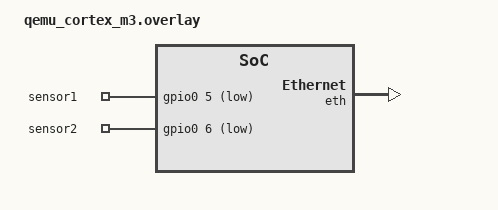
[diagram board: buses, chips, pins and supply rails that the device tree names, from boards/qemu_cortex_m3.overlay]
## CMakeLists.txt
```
# SPDX-License-Identifier: Apache-2.0

cmake_minimum_required(VERSION 3.20.0)

set(ZEPHYR_EXTRA_MODULES "${CMAKE_CURRENT_SOURCE_DIR}/camera_service")

find_package(Zephyr REQUIRED HINTS $ENV{ZEPHYR_BASE})
project(tracker)

include_directories(./include/)

file(GLOB_RECURSE SRC ${CMAKE_SOURCE_DIR} "src/*.c")

target_sources(app PRIVATE ${SRC})
```

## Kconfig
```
menu "Zephyr"
source "Kconfig.zephyr"
endmenu

menu "Tracker Configuration"
    menu "Vehicle Speed Detection"

    config VEHICLE_SPEED_DETECTION
        bool "Enable Vehicle Speed Detection"
        default y
        help
            This option enables the vehicle speed detection feature in the system.
            It allows the system to monitor and report the speed of the vehicle in real-time.
            This feature is essential for applications that require speed monitoring and control.
    config RADAR_SENSOR_DISTANCE_MM
        int "Distance between sensors (mm)"
        range 100 1000
        depends on VEHICLE_SPEED_DETECTION
        help
            The physical distance between the two magnetic sensors in millimeters.
            This value is used to calculate vehicle speed when a vehicle passes
            over both sensors. A larger distance generally provides more accurate
            speed measurements but requires more space for installation.
    
    config RADAR_SPEED_LIMIT_KMH
        int "Maximum speed permited (km/h)"
        range 10 300
        default 60
        depends on VEHICLE_SPEED_DETECTION
        help
            The maximum allowed vehicle speed in kilometers per hour.
            This value is used to trigger alarms or log over-speed events
            when a vehicle's calculated speed exceeds this limit.
            Adjust this setting according to local traffic regulations.

    config SENSOR_DEBOUNCE_MS
        int "Sensor debounce time (ms)"
        range 10 500
        default 50
        depends on VEHICLE_SPEED_DETECTION
        help
            The debounce time for the sensors in milliseconds. This is the time
            that the system will wait after detecting a signal from one sensor
            before considering it valid. A longer debounce time can help to filter
            out noise and false signals, but may also delay the detection of a vehicle.
            A value of 10ms is generally a good starting point.
    endmenu
    
    menu "Thread Configuration"
        config THREAD_STACK_SIZE
            int "Max stack size used in threads"
            default 1024
            help
                The maximum stack size used in threads. This value is used to
                allocate the stack space for each thread. A larger stack size
                allows for more complex operations and more local variables,
                but also consumes more memory. A value of 1024 bytes is generally
                a good starting point for most applications.

        config THREAD_PRIORITY
            int "Thread priority"
            default 5
            range 0 10
            help
                The priority of the threads in the system. This value determines
                the order in which threads are scheduled for execution. A higher
                priority value means that the thread will be executed before
                lower priority threads. A value of 5 is generally a good starting
                point for most applications.
    endmenu

    menu "SNTP Configuration"
        config DEFAULT_SNTP_SERVER
            string "Default SNTP server"
            default "200.160.7.186"
            help
                The default SNTP server to use for time synchronization. This
                server will be used if no other server is specified. The server
                should be reachable from the network and should support SNTP
                requests.

        config TIME_SYNC_INTERVAL_MS
            int "Time synchronization interval (ms)"
            default 3600000
            range 60000 86400000
            help
                The interval in milliseconds at which the system will synchronize
                its time with the SNTP server. A value of 3600000 ms (1 hour) is
                a good starting point for most applications, but can be adjusted
                based on the application's requirements.
        
        config NUMBER_OF_RETRIES
            int "Number of retries for SNTP requests"
            default 3
            range 1 10
            help
                The number of times the system will retry to synchronize time with
                the SNTP server if the initial request fails. A value of 3 is a good
                starting point, but can be adjusted based on network reliability and
                application requirements. 
    endmenu

    menu "HTTP Client Configuration"
        config SERVER_HOSTNAME
            string "Server hostname"
            default "192.168.0.12"
            help
                The hostname of the server to which the HTTP client will connect.
                This should be a valid hostname that resolves to an IP address
                reachable from the device. The default is set to "example.com",
                but should be changed to the actual server you want to connect to.

        config SERVER_PORT
            int "Server port"
            default 5000
            range 1 65535
            help
                The port number on which the server is listening for HTTP requests.
                The default is set to 80, which is the standard port for HTTP traffic.
                If your server uses a different port, you should change this value accordingly.

        config SERVER_URL
            string "Server URL"
            default "/api/speed-infractions"
            help
                The URL path on the server to which the HTTP client will send requests.
                This should be set to the specific endpoint that the server expects for
                receiving data. The default is set to "/api/speed-infractions", but should be changed
                to match your server's API.
        
        config CLIENT_MAX_RECV_BUF_LEN
            int "Maximum receive buffer length"
            default 1024
            range 256 8192
            help
                The maximum length of the receive buffer for the HTTP client.
                This value determines how much data the client can read from the server
                in a single response. A larger buffer allows for larger responses,
                but consumes more memory. A value of 1024 bytes is generally a good starting point.
        
        config RECV_BUF_LEN
            int "Receive buffer length"
            default 512
            range 128 4096
            help
                The length of the receive buffer used by the HTTP client. This buffer
                is used to store incoming data from the server. A larger buffer allows
                for more data to be received at once, but also consumes more memory.
                A value of 512 bytes is generally a good starting point for most applications.
        
        config RECV_TIMEOUT_MS
            int "Receive timeout (ms)"
            default 5000
            range 1000 30000
            help
                The timeout in milliseconds for receiving data from the server.
                If no data is received within this time, the client will consider
                the request failed. A value of 5000 ms (5 seconds) is a good starting point,
                but can be adjusted based on network conditions and application requirements.

    endmenu

    menu "Simulation Configuration"
        config SYSTEM_SIMULATION
            bool "Enable system simulation"
            default n
            help
                This option enables the system simulation mode. In this mode,
                the system will simulate the behavior of the vehicle speed detection
                system without actually using any hardware. This is useful for
                testing and debugging purposes.
        config SIMULATION_SPEED
            int "Simulation speed (km/h)"
            range 0 300
            default 60
            depends on SYSTEM_SIMULATION
            help
                The speed of the simulated vehicle in kilometers per hour. This
                value is used to simulate the behavior of the vehicle speed detection
                system. A value of 60 km/h is generally a good starting point for
                most applications.
    endmenu
endmenu
```

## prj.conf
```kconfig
# ===== GENERAL SYSTEM CONFIGURATION =====
CONFIG_BOOT_BANNER=n
CONFIG_POSIX_API=y
CONFIG_MAIN_STACK_SIZE=4096
CONFIG_SYSTEM_SIMULATION=y

# ===== HARDWARE PERIPHERALS =====
# GPIO Configuration
CONFIG_GPIO=y
CONFIG_GPIO_STELLARIS=y
CONFIG_GPIO_GET_CONFIG=y

# RTC Configuration
CONFIG_RTC=y

# Random Number Generation
CONFIG_ENTROPY_GENERATOR=y
CONFIG_TEST_RANDOM_GENERATOR=y

# ===== STORAGE AND SETTINGS =====
CONFIG_SETTINGS=y
CONFIG_FLASH=y
CONFIG_FLASH_MAP=y
CONFIG_NVS=y

# ===== NETWORKING BASE =====
CONFIG_NETWORKING=y
CONFIG_NET_CONNECTION_MANAGER=y
CONFIG_NET_SOCKETS=y
CONFIG_NET_IPV4=y
CONFIG_NET_IPV6=y
CONFIG_NET_QEMU_ETHERNET=y
CONFIG_NET_QEMU_USER=y

# ===== NETWORK PROTOCOLS =====
CONFIG_NET_UDP=y
CONFIG_NET_TCP=y
CONFIG_SNTP=y
CONFIG_NET_SOCKETS_POLL_MAX=5

# ===== NETWORK INTERFACE CONFIGURATION =====
CONFIG_NET_CONFIG_SETTINGS=y
CONFIG_NET_CONFIG_AUTO_INIT=y
CONFIG_NET_CONFIG_NEED_IPV4=y
CONFIG_NET_DHCPV4=y
CONFIG_NET_DHCPV6=y
# CONFIG_NET_CONFIG_MY_IPV4_ADDR="192.168.0.100"
# CONFIG_NET_CONFIG_MY_IPV4_NETMASK="255.255.255.0"
# CONFIG_NET_CONFIG_MY_IPV4_GW="192.168.0.1"

# ===== ETHERNET CONFIGURATION =====
CONFIG_NET_L2_ETHERNET=y
CONFIG_ETH_STELLARIS=y
CONFIG_NET_SLIP_TAP=n

# ===== DNS CONFIGURATION =====
CONFIG_DNS_RESOLVER=y
CONFIG_DNS_SERVER_IP_ADDRESSES=y
CONFIG_DNS_SERVER1="8.8.8.8"

# ===== NETWORK BUFFERS =====
CONFIG_NET_BUF_RX_COUNT=16
CONFIG_NET_BUF_TX_COUNT=16
CONFIG_NET_PKT_RX_COUNT=16
CONFIG_NET_PKT_TX_COUNT=16
CONFIG_NET_CONTEXT_NET_PKT_POOL=y

# ===== NETWORK MANAGEMENT =====
CONFIG_NET_MGMT=y
CONFIG_NET_MGMT_EVENT=y
CONFIG_NET_MGMT_EVENT_INFO=y

# ===== LOGGING =====
CONFIG_LOG=y
CONFIG_LOG_DEFAULT_LEVEL=3
CONFIG_NET_LOG=n

# ===== CAMERA SERVICE =====
CONFIG_ZBUS=y
CONFIG_ZBUS_MSG_SUBSCRIBER=y
CONFIG_TEST_RANDOM_GENERATOR=y
CONFIG_QEMU_ICOUNT=n

# ===== DISPLAY DRIVER =====
CONFIG_DISPLAY=y
CONFIG_DUMMY_DISPLAY=y

# ===== HTTP CLIENT =====
CONFIG_HTTP_CLIENT=y

# ===== JSON LIBRARY =====
CONFIG_JSON_LIBRARY=y
```

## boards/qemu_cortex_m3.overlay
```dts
#include <zephyr/dt-bindings/gpio/gpio.h>
/ {
    aliases {
        sensor1 = &gpio0;
        sensor2 = &gpio0;
    };

    sensors {
        compatible = "gpio-keys";
        debounce-interval-ms = <10>;
        sensor1: sensor_1{
            gpios = <&gpio0 5 GPIO_ACTIVE_LOW>;
        };

        sensor2: sensor_2{
            gpios = <&gpio0 6 GPIO_ACTIVE_LOW>;
        };
    };
    
    dummy_dc: dummy_display_controller {
        compatible = "zephyr,dummy-dc";
        width = <320>;
        height = <240>;
        status = "okay";
    };
    chosen {
        zephyr,display = &dummy_dc;
    };
};
&eth {
    status = "okay";
};
```

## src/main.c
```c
#include "camera_handler.h"
#include "camera_service.h"
#include "data_http_client.h"
#include "display.h"
#include "rtc.h"
#include "sensors.h"
#include "validate_plate.h"

LOG_MODULE_REGISTER(main, LOG_LEVEL_INF);

ZBUS_MSG_SUBSCRIBER_DEFINE(sensor_consumer);

static struct rtc_time latest_time;
static bool time_valid = false;

/**
 * @brief Validate the speed data and process it if valid.
 *
 * @param speed Speed in km/h to validate.
 * @param time_valid Indicates if the time data is valid.
 * @param latest_time Pointer to the latest time structure.
 * @return int
 */
static int validate_and_process_speed(int32_t speed, bool time_valid, struct rtc_time *latest_time);

int main(void)
{
	int err;
	struct sensor_event evt;
	const struct zbus_channel *evt_chan;

	err = display_speed_init();
	if (err < 0) {
		LOG_ERR("Failed to initialize display: %d", err);
		return 0;
	}

	err = sensors_init();
	if (err < 0) {
		LOG_ERR("Failed to initialize sensors");
		return 0;
	}

	LOG_INF("Vehicle detection system started");

	while (1) {
		if (k_msgq_get(&time_msgq, &latest_time, K_NO_WAIT) == 0) {
			time_valid = true;
			LOG_DBG("Time updated: %02d:%02d:%02d %02d/%02d/%04d", latest_time.tm_hour,
				latest_time.tm_min, latest_time.tm_sec, latest_time.tm_mday,
				latest_time.tm_mon + 1, latest_time.tm_year);
		}

		k_sleep(K_MSEC(500));

#ifdef CONFIG_SYSTEM_SIMULATION
		err = sensors_simulate_vehicle_detection(90);
		if (err < 0) {
			LOG_ERR("Failed to simulate vehicle detection: %d", err);
		}
#endif

		err = zbus_sub_wait_msg(&sensor_consumer, &evt_chan, &evt, K_FOREVER);
		if (err < 0) {
			if (err == -EAGAIN) {
				continue;
			}

			LOG_ERR("Failed to wait for sensor event: %d", err);
			continue;
		}

		if (evt.vehicle_detected) {
			int32_t speed = evt.speed_kmh;

			err = validate_and_process_speed(speed, time_valid, &latest_time);
			if (err < 0) {
				LOG_ERR("Failed to process speed data: %d", err);
				continue;
			}
		}
	}
}

static int validate_and_process_speed(int32_t speed, bool time_valid, struct rtc_time *latest_time)
{
	char timestamp[32];

	if (speed < 0 || speed > 500) {
		LOG_WRN("Invalid speed value: %d km/h - ignoring", speed);
		return -EINVAL;
	}

	char speed_text[32];
	snprintf(speed_text, sizeof(speed_text), "Speed: %d km/h", speed);

	int err = display_speed_show(speed_text);
	if (err < 0) {
		LOG_ERR("Failed to write speed to display: %d", err);
		return err;
	}

	if (speed > CONFIG_RADAR_SPEED_LIMIT_KMH) {
		LOG_INF("Speed violation detected! %d km/h", speed);

		if (time_valid && latest_time != NULL) {
			LOG_INF("Speed violation at %02d:%02d:%02d %02d/%02d/%04d",
				latest_time->tm_hour, latest_time->tm_min, latest_time->tm_sec,
				latest_time->tm_mday, latest_time->tm_mon + 1,
				latest_time->tm_year);
			const char *plate = NULL;
			const char *hash = NULL;
			char country[3];

			if (camera_handler_capture(&plate, &hash) == 0) {
				LOG_INF("Captured plate: %s", plate);
				LOG_DBG("Captured image hash: %s", hash);
				if (is_valid_mercosul_plate(plate, country)) {
					LOG_INF("Captured plate is valid and is from: %s", country);
					if (time_valid) {
						snprintf(timestamp, sizeof(timestamp),
							 "%02d:%02d:%02d %02d/%02d/%04d",
							 latest_time->tm_hour, latest_time->tm_min,
							 latest_time->tm_sec, latest_time->tm_mday,
							 latest_time->tm_mon + 1,
							 latest_time->tm_year);
					} else {
						strncpy(timestamp, "N/A", sizeof(timestamp));
					}
					err = send_infraction_data(speed, plate, country,
								   timestamp);
					if (err < 0) {
						LOG_ERR("Failed to send infraction data: %d", err);
					} else {
						LOG_INF("Infraction data sent successfully");
					}
				} else {
					LOG_INF("Captured plate is invalid!");
					/*TODO: send to python server that the plate is not valid*/
					err = send_infraction_data(speed, plate, "N/A", "N/A");
					if (err < 0) {
						LOG_ERR("Failed to send infraction data for "
							"invalid plate: %d",
							err);
					} else {
						LOG_INF("Infraction data for invalid plate sent "
							"successfully");
					}
				}
			} else {
				LOG_ERR("Failed to capture plate");
				return -EIO;
			}
		} else {
			struct rtc_time now;

			int ret = tracker_get_time(&now);
			if (ret == 0) {
				LOG_INF("Speed detected at %02d:%02d:%02d", now.tm_hour, now.tm_min,
					now.tm_sec);
			} else {
				LOG_ERR("Failed to get SNTP time");
			}
		}
	}

	return 0;
}
```

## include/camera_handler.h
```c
#include <zephyr/kernel.h>
#include <zephyr/logging/log.h>

/**
 * @brief Captures a simulated image via camera.
 *
 * Triggers the camera service via ZBUS, waits for a response, and returns the data.
 *
 * @param[out] plate Pointer to the captured license plate string.
 * @param[out] hash Pointer to the image hash string.
 * @return 0 on success, negative value on error.
 */
int camera_handler_capture(const char **plate, const char **hash);
```

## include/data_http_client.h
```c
#ifndef DATA_HTTP_CLIENT_H
#define DATA_HTTP_CLIENT_H

#include <zephyr/kernel.h>
#include <zephyr/logging/log.h>
#include <zephyr/net/http/client.h>
#include <zephyr/net/socket.h>

#include <stdint.h>

/**
 * @brief Send infraction data to the server.
 *
 * @param speed Speed in km/h of the vehicle.
 * @param plate Vehicle license plate number.
 * @param country Country code of the vehicle.
 * @param timestamp Timestamp of the infraction in ISO 8601 format (YYYY-MM-DDTHH:MM:SSZ).
 * @return 0 on success, negative error code on failure.
 */
int send_infraction_data(int32_t speed, const char *plate, const char *country,
			 const char *timestamp);

#endif // DATA_HTTP_CLIENT_H
```

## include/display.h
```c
#ifndef DISPLAY_H
#define DISPLAY_H
#include <zephyr/device.h>
#include <zephyr/drivers/display.h>
#include <zephyr/logging/log.h>

/**
 * @brief Initialize the display device and turn off display blanking.
 *
 * @return 0 on success, otherwise negative error code on failure.
 */
int display_speed_init(void);

/**
 * @brief Show the speed on the display.
 *
 * @param text The text to display, typically the speed in km/h.
 * @return 0 on success, otherwise negative error code on failure.
 */
int display_speed_show(const char *text);

#endif /* DISPLAY_H */
```

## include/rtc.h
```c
#ifndef RTC_H
#define RTC_H

#include <zephyr/device.h>
#include <zephyr/drivers/rtc.h>
#include <zephyr/kernel.h>
#include <zephyr/logging/log.h>
#include <zephyr/net/net_ip.h>
#include <zephyr/net/sntp.h>
#include <zephyr/net/socket.h>
#include <zephyr/settings/settings.h>

#include <time.h>

#include <stdbool.h>
#include <stdint.h>

extern struct k_msgq time_msgq;

/**
 * @brief Function to get the current time from SNTP server.
 *
 * @param time Pointer to the rtc_time structure to store the retrieved time.
 * @return int 0 on success, negative error code on failure.
 */
int tracker_get_time(struct rtc_time *time);

#endif /* RTC_H */
```

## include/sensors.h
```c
#ifndef SENSORS_H
#define SENSORS_H

#include "zephyr/zbus/zbus.h"
#include <zephyr/device.h>
#include <zephyr/drivers/gpio.h>
#include <zephyr/kernel.h>
#include <zephyr/logging/log.h>

#include <stdbool.h>
#include <stdint.h>

struct sensor_event {
	int32_t speed_kmh;
	bool vehicle_detected;
};

/**
 * @brief Construct a new zbus chan declare object
 *
 */
ZBUS_CHAN_DECLARE(chan_sensors_evt);

/**
 * @brief Initialize the sensors and configure GPIO pins.
 *
 * @return 0 on success, otherwise negative error code on failure.
 */
int sensors_init(void);

/**
 * @brief Trigger a sensor manually for testing purposes.
 *
 * @param sensor_num Sensor number to trigger (1 or 2).
 * @return 0 on success, otherwise negative error code on failure.
 */
int sensors_simulate_vehicle_detection(int32_t speed_kmh);

#endif /* SENSORS_H */
```

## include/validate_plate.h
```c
#ifndef VALIDATE_PLATE_H
#define VALIDATE_PLATE_H

#include <ctype.h>
#include <string.h>
#include <zephyr/kernel.h>

/**
 * @brief Validates a license plate and determines its country of origin.
 *
 * This function checks if the given license plate string matches the format
 * of a valid plate from Brazil (BR), Argentina (AR), or Paraguay (PY).
 * If valid, it copies the corresponding country code into the output parameter.
 *
 * @param plate        The license plate string to validate.
 * @param country_out  A pointer to a char array where the country code ("BR", "AR", "PY") will be
 * stored if valid.
 *
 * @return true if the plate is valid and matches one of the known formats, false otherwise.
 */

bool is_valid_mercosul_plate(const char *plate, char *country_out);

#endif /* VALIDATE_PLATE_H */
```

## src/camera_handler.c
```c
#include "camera_handler.h"
#include "camera_service.h"

LOG_MODULE_REGISTER(camera_handler, LOG_LEVEL_INF);

int camera_handler_capture(const char **plate, const char **hash)
{
	int ret = camera_api_capture(K_MSEC(500));
	if (ret < 0) {
		LOG_ERR("Failed to trigger camera capture");
		return ret;
	}

	struct msg_camera_evt msg;

	if (zbus_chan_read(&chan_camera_evt, &msg, K_MSEC(500)) != 0) {
		LOG_ERR("Timeout waiting for camera data");
		return -1;
	}

	if (msg.type == MSG_CAMERA_EVT_TYPE_DATA && msg.captured_data) {
		*plate = msg.captured_data->plate;
		*hash = msg.captured_data->hash;
		return 0;
	} else if (msg.type == MSG_CAMERA_EVT_TYPE_ERROR) {
		LOG_ERR("Camera error: %d", msg.error_code);
		return msg.error_code;
	}

	LOG_ERR("Invalid camera message type");
	return -1;
}
```

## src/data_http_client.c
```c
#include <errno.h>
#include <zephyr/kernel.h>
#include <zephyr/logging/log.h>
#include <zephyr/net/http/client.h>
#include <zephyr/net/socket.h>

#include "data_http_client.h"

LOG_MODULE_REGISTER(data_http_client, LOG_LEVEL_INF);

static char recv_buf_data[CONFIG_RECV_BUF_LEN];
static char response_buf[CONFIG_CLIENT_MAX_RECV_BUF_LEN];

/**
 * @brief Callback function to handle HTTP responses
 *
 * @param rsp Pointer to the HTTP response structure
 * @param final_data Final call status of the HTTP response
 * @param user_data User data pointer (not used in this case)
 */
static void response_cb(struct http_response *rsp, enum http_final_call final_data,
			void *user_data);

/**
 * @brief Prepare JSON data for sending infraction data
 *
 * @param buffer pointer to the buffer where JSON data will be stored
 * @param len size of the buffer
 * @param speed Speed in km/h
 * @param plate Plate number of the vehicle
 * @param country Respective country of the vehicle's plate
 * @param timestamp Timestamp of the infraction in "HH:MM:SS DD/MM/YYYY" format, or NULL if not
 * available
 * @return 0 if successful, otherwise negative error code
 */
static int prepare_json_data(char *buffer, size_t len, int32_t speed, const char *plate,
			     const char *country, const char *timestamp);

/**
 * @brief Fuction to connect to the HTTP server
 *
 * @return 0 if successful, otherwise negative error code
 */
static int connect_http_client(void);

static void response_cb(struct http_response *rsp, enum http_final_call final_data, void *user_data)
{
	if (final_data == HTTP_DATA_FINAL) {
		LOG_INF("Response status %s (%d)", rsp->http_status, rsp->http_status_code);
	}

	if (rsp->body_frag_len > 0) {
		LOG_INF("Response body: %.*s", rsp->body_frag_len, (char *)rsp->body_frag_start);
	}
}

static int prepare_json_data(char *buffer, size_t len, int32_t speed, const char *plate,
			     const char *country, const char *timestamp)
{
	int offset = 0;

	offset = snprintf(buffer, len, "{\"speed\":%d,\"plate\":\"%s\",\"country\":\"%s\"", speed,
			  plate, country);

	if (timestamp != NULL) {
		offset +=
			snprintf(buffer + offset, len - offset, ",\"timestamp\":\"%s\"", timestamp);
	}

	offset += snprintf(buffer + offset, len - offset, "}");

	LOG_INF("offset: %d, buffer: %s", offset, buffer);

	return offset;
}

static int connect_http_client(void)
{
	int sock;
	int ret;
	struct sockaddr_in addr;

	sock = socket(AF_INET, SOCK_STREAM, IPPROTO_TCP);
	if (sock < 0) {
		LOG_ERR("Failed to create socket: %d", errno);
		return -errno;
	}

	memset(&addr, 0, sizeof(addr));
	addr.sin_family = AF_INET;
	addr.sin_port = htons(CONFIG_SERVER_PORT);

	ret = inet_pton(AF_INET, CONFIG_SERVER_HOSTNAME, &addr.sin_addr);
	if (ret <= 0) {
		LOG_ERR("Invalid server address: %s", CONFIG_SERVER_HOSTNAME);
		close(sock);
		return -EINVAL;
	}

	ret = connect(sock, (struct sockaddr *)&addr, sizeof(addr));
	if (ret < 0) {
		LOG_ERR("Cannot connect to %s:%d (%d)", CONFIG_SERVER_HOSTNAME, CONFIG_SERVER_PORT,
			-errno);
		close(sock);
		return -errno;
	}

	return sock;
}

int send_infraction_data(int32_t speed, const char *plate, const char *country,
			 const char *timestamp)
{
	struct http_request req;
	int sock;
	int ret;
	char json_data[512];
	size_t json_len;

	json_len =
		prepare_json_data(json_data, sizeof(json_data), speed, plate, country, timestamp);

	LOG_INF("Sending infraction data: %s", json_data);

	sock = connect_http_client();
	if (sock < 0) {
		return sock;
	}

	static const char *headers[] = {"Content-Type: application/json\r\n",
					"Connection: close\r\n", "Accept: application/json\r\n",
					NULL};

	memset(&req, 0, sizeof(req));
	req.method = HTTP_POST;
	req.url = CONFIG_SERVER_URL;
	req.host = CONFIG_SERVER_HOSTNAME;
	req.protocol = "HTTP/1.1";
	req.payload = json_data;
	req.payload_len = json_len;
	req.header_fields = headers;
	req.response = response_cb;
	req.recv_buf = recv_buf_data;
	req.recv_buf_len = sizeof(recv_buf_data);

	ret = http_client_req(sock, &req, CONFIG_RECV_TIMEOUT_MS, response_buf);

	close(sock);

	if (ret < 0) {
		LOG_ERR("HTTP request failed: %d", ret);
		return ret;
	}

	LOG_INF("HTTP request completed, response length: %d", ret);
	return 0;
}
```

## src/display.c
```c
#include "display.h"

LOG_MODULE_REGISTER(display, LOG_LEVEL_INF);

const struct device *display_dev;

/**
 * @brief Render the given text on the display.
 *
 * @param text The text to display.
 * @return 0 on success, otherwise negative error code on failure.
 */
static int display_speed_write(const char *text);

/**
 * @brief Clear the speed display by writing a blank buffer to the display.
 *
 * @return 0 on success, otherwise negative error code on failure.
 */
static int display_speed_clear(void);

int display_speed_init(void)
{
	display_dev = DEVICE_DT_GET(DT_CHOSEN(zephyr_display));
	if (!device_is_ready(display_dev)) {
		LOG_ERR("Display device not ready");
		return -ENODEV;
	}

	LOG_INF("Display device initialized: %s", display_dev->name);
	int ret = display_blanking_off(display_dev);
	if (ret < 0) {
		LOG_ERR("Failed to turn off display blanking: %d", ret);
		return ret;
	}
	LOG_INF("Display blanking turned off");
	return 0;
}

static int display_speed_clear(void)
{
	if (!display_dev) {
		LOG_ERR("Display device not initialized");
		return -ENODEV;
	}

	struct display_buffer_descriptor desc = {
		.buf_size = 1,
		.width = 320,
		.height = 240,
		.pitch = 320,
	};

	uint8_t clear_buf[1] = {0};
	return display_write(display_dev, 0, 0, &desc, clear_buf);
}

static int display_speed_write(const char *text)
{
	int err = 0;
	if (!display_dev) {
		LOG_ERR("Display device not initialized");
		return -ENODEV;
	}

	err = display_speed_clear();
	if (err < 0) {
		LOG_ERR("Failed to clear display: %d", err);
		return err;
	}

	struct display_buffer_descriptor desc = {
		.buf_size = strlen(text),
		.width = 320,
		.height = 240,
		.pitch = 320,
	};

	return display_write(display_dev, 0, 0, &desc, (const uint8_t *)text);
}

int display_speed_show(const char *text)
{
	if (!display_dev) {
		LOG_ERR("Display device not initialized");
		return -ENODEV;
	}

	int err = display_speed_write(text);
	if (err < 0) {
		LOG_ERR("Failed to write text to display: %d", err);
		return err;
	}

	LOG_INF("Speed: %s", text);
	return 0;
}
```

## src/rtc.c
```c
#include "rtc.h"

LOG_MODULE_REGISTER(rtc, LOG_LEVEL_DBG);

#define TIME_QUEUE_SIZE 5

K_MSGQ_DEFINE(time_msgq, sizeof(struct rtc_time), TIME_QUEUE_SIZE, 4);

static struct sys_time {
	char server[64];
	int8_t timezone;
} self = {.server = CONFIG_DEFAULT_SNTP_SERVER, .timezone = 0};

/**
 * @brief Function to get the current time from SNTP server.
 *
 * @param p1 Void pointer to the first parameter (not used).
 * @param p2 Void pointer to the second parameter (not used).
 * @param p3 Void pointer to the third parameter (not used).
 */
static void time_thread_function(void *p1, void *p2, void *p3);

int tracker_get_time(struct rtc_time *time)
{
	struct sntp_ctx ctx;
	struct sntp_time datetime;
	struct sockaddr_in server_addr;
	int err = 0;

	server_addr.sin_family = AF_INET;
	server_addr.sin_port = htons(123);

	memset(&ctx, 0, sizeof(ctx));

	err = inet_pton(AF_INET, self.server, &server_addr.sin_addr);

	if (err < 0) {
		LOG_ERR("Invalid SNTP server address: %d", err);
		return -EINVAL;
	}

	err = sntp_init(&ctx, (struct sockaddr *)&server_addr, sizeof(struct sockaddr_in));

	if (err < 0) {
		LOG_ERR("Failed to initialize SNTP: %d", err);
		return err;
	}

	err = sntp_query(&ctx, 4 * MSEC_PER_SEC, &datetime);

	if (err < 0) {
		LOG_ERR("Failed to query SNTP: %d", err);
		goto close_sntp;
	}

close_sntp:

	sntp_close(&ctx);

	time_t unix_time = datetime.seconds;
	unix_time += self.timezone * 3600;

	struct tm tm_info;
	if (gmtime_r(&unix_time, &tm_info) == NULL) {
		LOG_ERR("Failed to convert time to UTC");
		return -EINVAL;
	}

	time->tm_sec = tm_info.tm_sec;
	time->tm_min = tm_info.tm_min;
	time->tm_hour = tm_info.tm_hour;
	time->tm_mday = tm_info.tm_mday;
	time->tm_mon = tm_info.tm_mon;
	time->tm_year = tm_info.tm_year + 1900;
	time->tm_wday = tm_info.tm_wday;
	time->tm_yday = tm_info.tm_yday;
	time->tm_isdst = tm_info.tm_isdst;

	return 0;
}

static void time_thread_function(void *p1, void *p2, void *p3)
{
	struct rtc_time time;
	int err;

	while (1) {
		err = tracker_get_time(&time);
		if (err == 0) {
			k_msgq_purge(&time_msgq);
			k_msgq_put(&time_msgq, &time, K_NO_WAIT);
		}
		k_sleep(K_SECONDS(1));
	}
}

K_THREAD_DEFINE(time_thread, 1024, time_thread_function, NULL, NULL, NULL, 3, 0, 0);
```

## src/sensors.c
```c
#include "sensors.h"
#include "zephyr/logging/log.h"
#include "zephyr/sys/util_macro.h"
#include "zephyr/zbus/zbus.h"

#define SENSOR_1 DEVICE_DT_GET(DT_ALIAS(sensor1))
#define SENSOR_2 DEVICE_DT_GET(DT_ALIAS(sensor2))

#define SENSOR1_PIN DT_GPIO_PIN(DT_NODELABEL(sensor1), gpios)
#define SENSOR2_PIN DT_GPIO_PIN(DT_NODELABEL(sensor2), gpios)

LOG_MODULE_REGISTER(sensors, LOG_LEVEL_DBG);

static int64_t sensor1_timestamp;
static int64_t sensor2_timestamp;
static int32_t latest_speed_kmh;
static bool vehicle_detected;
static bool system_initialized;

static struct gpio_callback sensor1_cb_data;
static struct gpio_callback sensor2_cb_data;

ZBUS_CHAN_DEFINE(chan_sensors_evt, struct sensor_event, NULL, NULL, ZBUS_OBSERVERS(sensor_consumer),
		 ZBUS_MSG_INIT(.speed_kmh = 0, .vehicle_detected = false));

/**
 * @brief Callback function for sensor 1.
 *
 * @param dev device pointer.
 * @param cb callback pointer.
 * @param pins pins that triggered the callback.
 */
static void sensor1_callback(const struct device *dev, struct gpio_callback *cb, uint32_t pins);

/**
 * @brief Callback function for sensor 2.
 *
 * @param dev device pointer.
 * @param cb callback pointer.
 * @param pins pins that triggered the callback.
 */
static void sensor2_callback(const struct device *dev, struct gpio_callback *cb, uint32_t pins);

/**
 * @brief Simulate vehicle detection for testing purposes.
 *
 * @param speed_kmh Speed in km/h to simulate.
 * @return 0 on success, otherwise negative error code on failure.
 */
int sensors_simulate_vehicle_detection(int32_t speed_kmh);

/**
 * @brief Trigger a sensor manually for testing purposes.
 *
 * @param sensor_num Sensor number to trigger (1 or 2).
 * @return 0 on success, otherwise negative error code on failure.
 */
int trigger_sensor_manually(int sensor_num);

static void sensor1_callback(const struct device *dev, struct gpio_callback *cb, uint32_t pins)
{
	sensor1_timestamp = k_uptime_get();
	LOG_INF("Sensor 1 triggered at %lld ms", sensor1_timestamp);
	vehicle_detected = true;
}

static void sensor2_callback(const struct device *dev, struct gpio_callback *cb, uint32_t pins)
{
	sensor2_timestamp = k_uptime_get();
	struct sensor_event evt = {
		.speed_kmh = latest_speed_kmh,
		.vehicle_detected = true,
	};
	int err = 0;

	LOG_INF("Sensor 2 triggered at %lld ms", sensor2_timestamp);

	int64_t time_diff_ms = sensor2_timestamp - sensor1_timestamp;

	if (time_diff_ms < 0) {
		LOG_ERR("Sensor 2 triggered before sensor 1");
		return;
	}

	if (IS_ENABLED(CONFIG_SYSTEM_SIMULATION)) {
		sensors_simulate_vehicle_detection(120);
		return;
	}

	if (time_diff_ms > 0) {
		float time_diff_s = time_diff_ms / 1000.0f;
		float speed_ms = CONFIG_RADAR_SENSOR_DISTANCE_MM / time_diff_s;
		latest_speed_kmh = (int32_t)(speed_ms * 3.6f);

		LOG_INF("Speed: %d km/h", latest_speed_kmh);

		err = zbus_chan_pub(&chan_sensors_evt, &evt, K_NO_WAIT);
		if (err < 0) {
			LOG_ERR("Failed to publish sensor event: %d", err);
		}
	} else {
		LOG_ERR("Invalid time difference");
	}
}

int sensors_init(void)
{
	int ret = 0;

	if (!device_is_ready(SENSOR_1) || !device_is_ready(SENSOR_2)) {
		LOG_ERR("Sensor devices not ready");
		return -ENODEV;
	}

	ret = gpio_pin_configure(SENSOR_1, SENSOR1_PIN, GPIO_INPUT);
	if (ret < 0) {
		LOG_ERR("Failed to configure sensor 1 pin: %d", ret);
		return ret;
	}

	ret = gpio_pin_configure(SENSOR_2, SENSOR2_PIN, GPIO_INPUT);
	if (ret < 0) {
		LOG_ERR("Failed to configure sensor 2 pin: %d", ret);
		return ret;
	}

	gpio_init_callback(&sensor1_cb_data, sensor1_callback, BIT(SENSOR1_PIN));
	ret = gpio_add_callback(SENSOR_1, &sensor1_cb_data);
	if (ret < 0) {
		LOG_ERR("Failed to add sensor 1 callback: %d", ret);
		return ret;
	}

	gpio_init_callback(&sensor2_cb_data, sensor2_callback, BIT(SENSOR2_PIN));
	ret = gpio_add_callback(SENSOR_2, &sensor2_cb_data);
	if (ret < 0) {
		LOG_ERR("Failed to add sensor 2 callback: %d", ret);
		return ret;
	}

	ret = gpio_pin_interrupt_configure(SENSOR_1, SENSOR1_PIN, GPIO_INT_EDGE_RISING);
	if (ret < 0) {
		LOG_ERR("Failed to configure sensor 1 interrupt: %d", ret);
		return ret;
	}

	ret = gpio_pin_interrupt_configure(SENSOR_2, SENSOR2_PIN, GPIO_INT_EDGE_FALLING);
	if (ret < 0) {
		LOG_ERR("Failed to configure sensor 2 interrupt: %d", ret);
		return ret;
	}

	LOG_INF("Sensors initialized");
	system_initialized = true;

	return 0;
}

int trigger_sensor_manually(int sensor_num)
{
	if (!system_initialized) {
		LOG_ERR("Sensors not initialized");
		return -EINVAL;
	}

	if (sensor_num == 1) {
		sensor1_callback(SENSOR_1, &sensor1_cb_data, BIT(SENSOR1_PIN));
	} else if (sensor_num == 2) {
		sensor2_callback(SENSOR_2, &sensor2_cb_data, BIT(SENSOR2_PIN));
	} else {
		LOG_ERR("Invalid sensor number: %d", sensor_num);
		return -EINVAL;
	}

	return 0;
}

int sensors_simulate_vehicle_detection(int32_t speed_kmh)
{
	static struct sensor_event evt_data;

	if (!system_initialized) {
		LOG_ERR("Sensors not initialized");
		return -EINVAL;
	}

	latest_speed_kmh = speed_kmh;
	vehicle_detected = true;

	evt_data.speed_kmh = latest_speed_kmh;
	evt_data.vehicle_detected = vehicle_detected;

	int err = zbus_chan_pub(&chan_sensors_evt, &evt_data, K_NO_WAIT);
	if (err < 0) {
		LOG_ERR("Failed to publish sensor event: %d", err);
		return err;
	}

	LOG_INF("Simulated vehicle detection at %d km/h", latest_speed_kmh);

	return 0;
}
```

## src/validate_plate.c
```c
#include "validate_plate.h"
/**
 * @brief Matches a license plate string against a pattern format.
 *
 * @param plate The input license plate string to validate.
 * @param format The format string used as a pattern.
 *
 * @return true if the plate matches the format; false otherwise.
 */
static bool match_format(const char *plate, const char *format);

/**
 * @brief Checks if the license plate matches Brazilian formats.
 *
 * Expected format: AAA9A99.
 *
 * @param plate The input license plate string.
 *
 * @return true if the plate matches a Brazilian format; false otherwise.
 */
static bool match_br(const char *plate);

/**
 * @brief Checks if the license plate matches Paraguayan formats.
 *
 * Supports both car format (AAAA 999) and motorcycle format (999 AAAA).
 *
 * @param plate The input license plate string.
 *
 * @return true if the plate matches a Paraguayan format; false otherwise.
 */
static bool match_py(const char *plate);

/**
 * @brief Checks if the license plate matches Argentine format.
 *
 * Expected format: AA 999 AA (with space characters).
 *
 * @param plate The input license plate string.
 *
 * @return true if the plate matches the Argentine format; false otherwise.
 */
static bool match_ar(const char *plate);

static bool match_format(const char *plate, const char *format)
{
	while (*plate && *format) {
		if (*format == 'A' && !isupper((unsigned char)*plate)) {
			return false;
		}
		if (*format == '9' && !isdigit((unsigned char)*plate)) {
			return false;
		}
		if (*format == ' ' && !isspace((unsigned char)*plate)) {
			return false;
		}
		plate++;
		format++;
	}
	return *plate == '\0' && *format == '\0';
}

static bool match_br(const char *plate)
{
	if (strlen(plate) != 7) {
		return false;
	}
	return match_format(plate, "AAA9A99");
}

static bool match_py(const char *plate)
{
	if (strlen(plate) != 8) {
		return false;
	}
	return match_format(plate, "AAAA 999") || match_format(plate, "999 AAAA");
}

static bool match_ar(const char *plate)
{
	if (strlen(plate) != 9 || strlen(plate) != 7) {
		return false;
	}
	return match_format(plate, "AA 999 AA") || match_format(plate, "A999AAA");
}

bool is_valid_mercosul_plate(const char *plate, char *country_out)
{
	if (match_br(plate)) {
		strcpy(country_out, "BR");
		return true;
	} else if (match_ar(plate)) {
		strcpy(country_out, "AR");
		return true;
	} else if (match_py(plate)) {
		strcpy(country_out, "PY");
		return true;
	}
	return false;
}
```
